AUTOSAR XML (schema 4-2-2)
package /Components
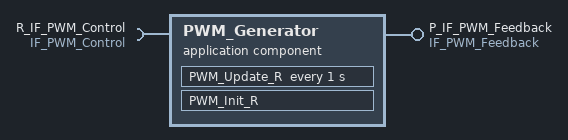
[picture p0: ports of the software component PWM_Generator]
  application sw component type PWM_Generator
    provide port P_IF_PWM_Feedback: provided-interface=IF_PWM_Feedback
    provide/require port PR_IF_Light_Params: provided-required-interface=IF_Light_Params
    require port R_IF_PWM_Control: required-interface=IF_PWM_Control
    behavior PWM_Generator_InternalBehavior
      data received event PWM_Setpoint_Received: start-on-event=PWM_Update_R
      init event PWM_Init_Event: start-on-event=PWM_Init_R
      timing event PWM_Update_1ms: start-on-event=PWM_Update_R, period=1
      runnable PWM_Init_R
        4 x parameter access:
          ParamAccess_PwmMaxDuty: accessed-parameter=PR_IF_Light_Params.pwm_max_duty
          ParamAccess_PwmMinDuty: accessed-parameter=PR_IF_Light_Params.pwm_min_duty
          ParamAccess_FaultCurrentThreshold: accessed-parameter=PR_IF_Light_Params.fault_current_threshold
          ParamAccess_RetryCount: accessed-parameter=PR_IF_Light_Params.retry_count
      runnable PWM_Update_R: minimum-start-interval=1
        data-receive-point-by-arguments:
          4 x access:
            Recv_Headlamp_Duty_SP: accessed-variable=R_IF_PWM_Control.headlamp_duty_setpoint
            Recv_TailLamp_Duty_SP: accessed-variable=R_IF_PWM_Control.tail_lamp_duty_setpoint
            Recv_LeftTurn_Duty_SP: accessed-variable=R_IF_PWM_Control.left_turn_duty_setpoint
            Recv_RightTurn_Duty_SP: accessed-variable=R_IF_PWM_Control.right_turn_duty_setpoint
        data-send-points:
          5 x access:
            Send_Headlamp_Current_Brightness: accessed-variable=P_IF_PWM_Feedback.headlamp_current_brightness
            Send_TailLamp_Current_Brightness: accessed-variable=P_IF_PWM_Feedback.tail_lamp_current_brightness
            Send_LeftTurn_Status: accessed-variable=P_IF_PWM_Feedback.left_turn_status
            Send_RightTurn_Status: accessed-variable=P_IF_PWM_Feedback.right_turn_status
            Send_Lamp_Fault_Code: accessed-variable=P_IF_PWM_Feedback.lamp_fault_code
